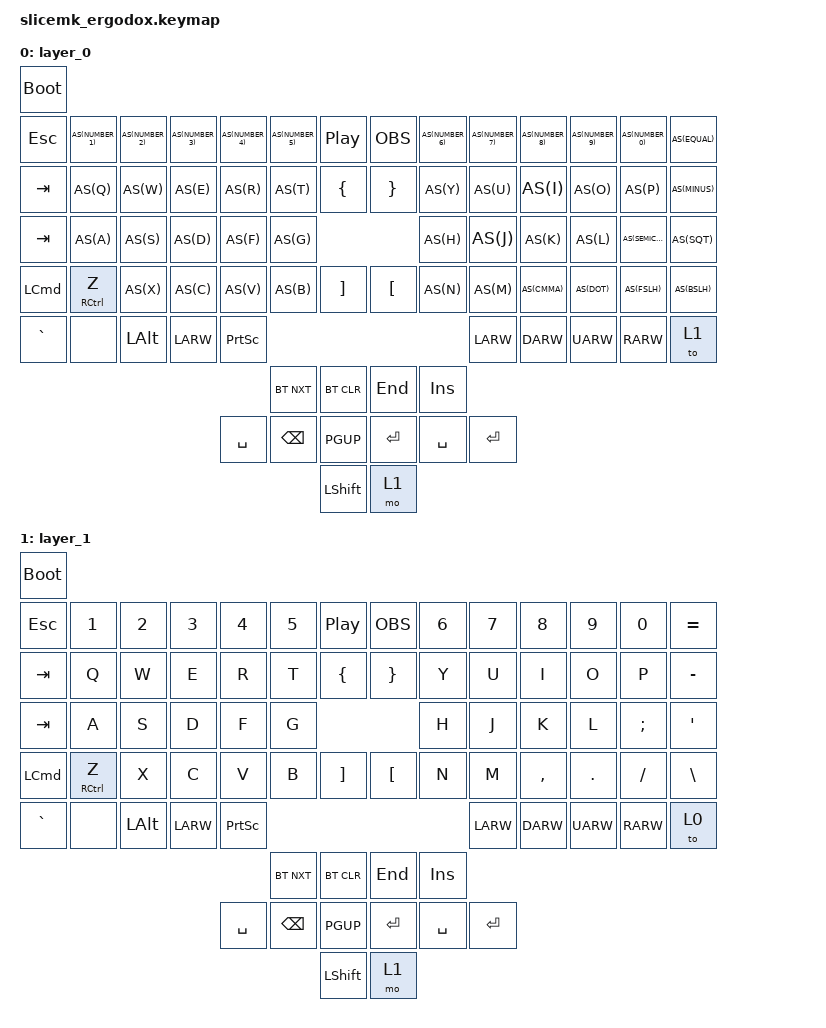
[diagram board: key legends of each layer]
#include <behaviors.dtsi>
#include <dt-bindings/zmk/bt.h>
#include <dt-bindings/zmk/keys.h>
#include <dt-bindings/zmk/outputs.h>

#define AS(keycode) &as LS(keycode) keycode     // Autoshift Macro
#define OBS RA(RS(RC(RG(O))))

/ {
	behaviors {
		as: auto_shift {
			  label = "as";
				compatible = "zmk,behavior-hold-tap";
				#binding-cells = <2>;
				quick_tap_ms = <0>;
				tapping_term_ms = <140>;
				require-prior-idle-ms = <70>;
				flavor = "tap-preferred";
				bindings = <&kp>, <&kp>;
		};
		rpi: require_prior_idle {
			  label = "rpi";
				compatible = "zmk,behavior-hold-tap";
				#binding-cells = <2>;
				flavor = "tap-preferred";
				tapping-term-ms = <200>;
				quick-tap-ms = <200>;
				require-prior-idle-ms = <125>;
				bindings = <&kp>, <&kp>;
		};
	};

	keymap {
		compatible = "zmk,keymap";

		layer_0 {
			bindings = <
				&bootloader
				&kp ESC         AS(NUMBER_1) AS(NUMBER_2) AS(NUMBER_3) AS(NUMBER_4) AS(NUMBER_5) &kp C_PLAY_PAUSE &kp OBS        AS(NUMBER_6) AS(NUMBER_7) AS(NUMBER_8) AS(NUMBER_9) AS(NUMBER_0)      AS(EQUAL)
				&kp TAB         AS(Q)        AS(W)        AS(E)        AS(R)        AS(T)      &kp LBRC           &kp RBRC       AS(Y)        AS(U)        AS(I)        AS(O)        AS(P)             AS(MINUS)
				&kp TAB         AS(A)        AS(S)        AS(D)        AS(F)        AS(G)                                        AS(H)        AS(J)        AS(K)        AS(L)        AS(SEMICOLON)     AS(SQT)
				&kp LCMD  &rpi  RCTRL Z      AS(X)        AS(C)        AS(V)        AS(B)      &kp RBKT           &kp LBKT       AS(N)        AS(M)        AS(CMMA)     AS(DOT)      AS(FSLH)          AS(BSLH)
				&kp GRAVE       &none        &kp LALT     &kp LARW     &kp PSCRN                                                          &kp LARW     &kp DARW     &kp UARW     &kp RARW          &to 1
				                                                                &bt BT_NXT     &bt BT_CLR         &kp END    &kp INS
				                                                   &kp SPC      &kp BSPC       &kp PGUP           &kp RET    &kp SPC      &kp RET
				                                                                               &kp LSHFT          &mo 1
			>;
		};

		layer_1 {
			bindings = <
				&bootloader
				&kp ESC        &kp NUMBER_1 &kp NUMBER_2 &kp NUMBER_3 &kp NUMBER_4 &kp NUMBER_5 &kp C_PLAY_PAUSE &kp OBS        &kp NUMBER_6 &kp NUMBER_7 &kp NUMBER_8 &kp NUMBER_9 &kp NUMBER_0      &kp EQUAL
				&kp TAB        &kp Q        &kp W        &kp E        &kp R        &kp T      &kp LBRC           &kp RBRC       &kp Y        &kp U        &kp I        &kp O        &kp P             &kp MINUS
				&kp TAB        &kp A        &kp S        &kp D        &kp F        &kp G                                        &kp H        &kp J        &kp K        &kp L        &kp SEMICOLON     &kp SQT
				&kp LCMD  &rpi RCTRL Z      &kp X        &kp C        &kp V        &kp B      &kp RBKT           &kp LBKT       &kp N        &kp M        &kp CMMA     &kp DOT      &kp FSLH          &kp BSLH
				&kp GRAVE      &none        &kp LALT     &kp LARW     &kp PSCRN                                                          &kp LARW     &kp DARW     &kp UARW     &kp RARW          &to 0
				                                                                &bt BT_NXT     &bt BT_CLR         &kp END    &kp INS
				                                                   &kp SPC      &kp BSPC       &kp PGUP           &kp RET    &kp SPC      &kp RET
				                                                                               &kp LSHFT          &mo 1
			>;
		};
	};
};
